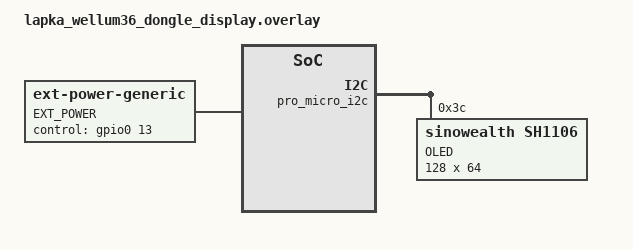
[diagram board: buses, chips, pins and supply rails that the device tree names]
#include "lapka_wellum36.dtsi"

&kscan0 {
	input-gpios
		= <&pro_micro 1  (GPIO_ACTIVE_LOW | GPIO_PULL_UP)>
		, <&pro_micro 16 (GPIO_ACTIVE_LOW | GPIO_PULL_UP)>
		, <&pro_micro 14 (GPIO_ACTIVE_LOW | GPIO_PULL_UP)>
		, <&pro_micro 18 (GPIO_ACTIVE_LOW | GPIO_PULL_UP)>
		, <&pro_micro 21 (GPIO_ACTIVE_LOW | GPIO_PULL_UP)>
		, <&pro_micro 2  (GPIO_ACTIVE_LOW | GPIO_PULL_UP)>
		, <&pro_micro 10 (GPIO_ACTIVE_LOW | GPIO_PULL_UP)>
		, <&pro_micro 15 (GPIO_ACTIVE_LOW | GPIO_PULL_UP)>
		, <&pro_micro 19 (GPIO_ACTIVE_LOW | GPIO_PULL_UP)>
		, <&pro_micro 20 (GPIO_ACTIVE_LOW | GPIO_PULL_UP)>
		, <&pro_micro 0  (GPIO_ACTIVE_LOW | GPIO_PULL_UP)>
		, <&pro_micro 3  (GPIO_ACTIVE_LOW | GPIO_PULL_UP)>
		, <&pro_micro 9  (GPIO_ACTIVE_LOW | GPIO_PULL_UP)>
		, <&pro_micro 4  (GPIO_ACTIVE_LOW | GPIO_PULL_UP)>
		, <&pro_micro 6  (GPIO_ACTIVE_LOW | GPIO_PULL_UP)>
		, <&pro_micro 8  (GPIO_ACTIVE_LOW | GPIO_PULL_UP)>
		, <&pro_micro 7  (GPIO_ACTIVE_LOW | GPIO_PULL_UP)>
		, <&pro_micro 5  (GPIO_ACTIVE_LOW | GPIO_PULL_UP)>
		;
};

/ {
    chosen {
        zmk,kscan = &kscan0;
        zephyr,display = &oled;
    };

    ext_power_ctrl: ext-power {
        compatible = "zmk,ext-power-generic";
        label = "EXT_POWER";
        control-gpios = <&gpio0 13 GPIO_ACTIVE_HIGH>;
        init-delay-ms = <50>;
    };
};

/* OLED */
&pro_micro_i2c {
    status = "okay";

    oled: sh1106@3c {
        compatible = "sinowealth,sh1106";
        reg = <0x3c>;
        label = "OLED";
        width = <128>;
        height = <64>;
        segment-offset = <2>;
        page-offset = <0>;
        display-offset = <0>;
        multiplex-ratio = <63>;
        inversion-on;
        prechargep = <0x22>;
    };
};
